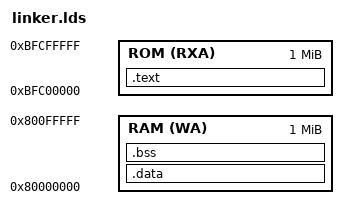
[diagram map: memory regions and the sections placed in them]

ENTRY(_start)

MEMORY
{
        /* ROM-based system */
        ROM (RXA) : ORIGIN = 0xBFC00000, LENGTH = 1M /* KSEG1, use ROM @ 0x1FC00000 */
        RAM (WA)  : ORIGIN = 0x80000000, LENGTH = 1M /* KSEG0, use RAM @ 0x00000000 */
}

SECTIONS
{
        /**********************************************************************
         *                                                                    *
         **********************************************************************/
        .text :
        {
                _stext = .;
                *(.vectors)
                *(.startup)
                *(.text)
                *(.text.*)
                *(.rodata)
                *(.rodata.*)
                *(.MIPS.abiflags)
                . = ALIGN(0x10);
                _etext = .;
        } > ROM
        /**********************************************************************
         *                                                                    *
         **********************************************************************/
        .data : AT(_etext)
        {
                _sdata = .;
                *(.data)
                *(.data.*)
                *(.sdata)
                *(.sdata.*)
                _sdata2 = .;
                *(.sdata2)
                . = ALIGN(0x10);
                _edata = .;
        } > RAM
        /**********************************************************************
         *                                                                    *
         **********************************************************************/
        .bss ADDR(.data) + SIZEOF(.data) (NOLOAD) :
        {
                _sbss = .;
                *(.bss)
                *(.bss.*)
                *(.sbss)
                *(.sbss.*)
                *(.dynbss)
                *(COMMON)
                *(.scommon)
                . = ALIGN(0x10);
                _ebss = .;
        } > RAM
        /**********************************************************************
         *                                                                    *
         **********************************************************************/
        .debug_info     : { *(.debug_info) }
        .debug_abbrev   : { *(.debug_abbrev) }
        .debug_aranges  : { *(.debug_aranges) }
        .debug_frame    : { *(.debug_frame) }
        .debug_line     : { *(.debug_line) }
        .debug_line_str : { *(.debug_line_str) }
        .debug_loclists : { *(.debug_loclists) }
        .debug_macro    : { *(.debug_macro) }
        .debug_names    : { *(.debug_names) }
        .debug_rnglists : { *(.debug_rnglists) }
        .debug_str      : { *(.debug_str) }
        /**********************************************************************
         *                                                                    *
         **********************************************************************/
        /DISCARD/ :
        {
                *(*)
        }
}

